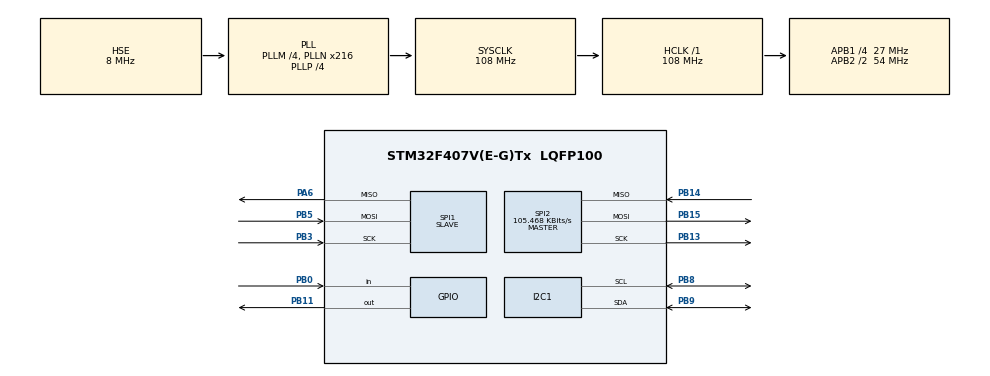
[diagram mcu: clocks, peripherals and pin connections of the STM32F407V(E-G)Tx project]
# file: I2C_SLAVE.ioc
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I2C1.GeneralCallMode=I2C_GENERALCALL_ENABLE
I2C1.OwnAddress=0x50
Mcu.Family=STM32F4
Mcu.Name=STM32F407V(E-G)Tx
Mcu.Package=LQFP100
NVIC.I2C1_ER_IRQn=true\:0\:0\:false\:false\:true\:true\:true
NVIC.I2C1_EV_IRQn=true\:0\:0\:false\:false\:true\:true\:true
NVIC.PriorityGroup=NVIC_PRIORITYGROUP_4
NVIC.SPI1_IRQn=true\:1\:0\:true\:false\:true\:true\:true
NVIC.SPI2_IRQn=true\:1\:0\:true\:false\:true\:true\:true
PA13.Mode=Serial_Wire
PA13.Signal=SYS_JTMS-SWDIO
PA14.Mode=Serial_Wire
PA14.Signal=SYS_JTCK-SWCLK
PA6.Mode=Full_Duplex_Slave
PA6.Signal=SPI1_MISO
PB0.Signal=GPIO_Input
PB11.GPIO_PuPd=GPIO_PULLUP
PB11.GPIO_Speed=GPIO_SPEED_FREQ_HIGH
PB11.PinState=GPIO_PIN_SET
PB11.Signal=GPIO_Output
PB13.Mode=Full_Duplex_Master
PB13.Signal=SPI2_SCK
PB14.Mode=Full_Duplex_Master
PB14.Signal=SPI2_MISO
PB15.Mode=Full_Duplex_Master
PB15.Signal=SPI2_MOSI
PB3.Mode=Full_Duplex_Slave
PB3.Signal=SPI1_SCK
PB5.Mode=Full_Duplex_Slave
PB5.Signal=SPI1_MOSI
PB8.Mode=I2C
PB8.Signal=I2C1_SCL
PB9.Mode=I2C
PB9.Signal=I2C1_SDA
PH0-OSC_IN.Mode=HSE-External-Oscillator
PH0-OSC_IN.Signal=RCC_OSC_IN
PH1-OSC_OUT.Mode=HSE-External-Oscillator
PH1-OSC_OUT.Signal=RCC_OSC_OUT
ProjectManager.HeapSize=0x200
ProjectManager.StackSize=0x400
ProjectManager.TargetToolchain=MDK-ARM V5.27
RCC.48MHZClocksFreq_Value=108000000
RCC.AHBFreq_Value=108000000
RCC.APB1CLKDivider=RCC_HCLK_DIV4
RCC.APB1Freq_Value=27000000
RCC.APB1TimFreq_Value=54000000
RCC.APB2CLKDivider=RCC_HCLK_DIV2
RCC.APB2Freq_Value=54000000
RCC.APB2TimFreq_Value=108000000
RCC.CortexFreq_Value=108000000
RCC.HCLKFreq_Value=108000000
RCC.HSE_VALUE=8000000
RCC.HSI_VALUE=16000000
RCC.LSE_VALUE=32768
RCC.PLLM=4
RCC.PLLN=216
RCC.PLLP=RCC_PLLP_DIV4
RCC.PLLSourceVirtual=RCC_PLLSOURCE_HSE
RCC.SYSCLKFreq_VALUE=108000000
RCC.SYSCLKSource=RCC_SYSCLKSOURCE_PLLCLK
RCC.VCOOutputFreq_Value=432000000
SPI1.Direction=SPI_DIRECTION_2LINES
SPI1.Mode=SPI_MODE_SLAVE
SPI1.VirtualType=VM_SLAVE
SPI2.BaudRatePrescaler=SPI_BAUDRATEPRESCALER_256
SPI2.CalculateBaudRate=105.468 KBits/s
SPI2.Direction=SPI_DIRECTION_2LINES
SPI2.Mode=SPI_MODE_MASTER
SPI2.VirtualType=VM_MASTER
board=custom

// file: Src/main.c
/* USER CODE BEGIN Header */
/**
  ******************************************************************************
  * @file           : main.c
  * @brief          : Main program body
  ******************************************************************************
  * @attention
  *
  * <h2><center>&copy; Copyright (c) 2020 STMicroelectronics.
  * All rights reserved.</center></h2>
  *
  * This software component is licensed by ST under BSD 3-Clause license,
  * the "License"; You may not use this file except in compliance with the
  * License. You may obtain a copy of the License at:
  *                        opensource.org/licenses/BSD-3-Clause
  *
  ******************************************************************************
  */
/* USER CODE END Header */

#include "main.h"
#include "i2c.h"
#include "spi.h"
#include "gpio.h"

/* USER CODE BEGIN Includes */
#include "string.h"
/* USER CODE END Includes */

/* USER CODE BEGIN PTD */
extern uint8_t slave_rec_buf[150];
extern uint8_t master_rec_buf[150];
/* USER CODE END PTD */

void SystemClock_Config(void);

int main(void)
{

  /* MCU Configuration--------------------------------------------------------*/

  /* Reset of all peripherals, Initializes the Flash interface and the Systick. */
  HAL_Init();

  /* Configure the system clock */
  SystemClock_Config();

  /* Initialize all configured peripherals */
  MX_GPIO_Init();
  MX_I2C1_Init();
  MX_SPI1_Init();
  MX_SPI2_Init();
  /* USER CODE BEGIN 2 */
//	slave_work();
		spi_slave_work();
  /* USER CODE END 2 */

  /* Infinite loop */
  /* USER CODE BEGIN WHILE */
  while (1)
  {
		spi_master_work();
    /* USER CODE END WHILE */

    /* USER CODE BEGIN 3 */
//		master_work();
//		memset(slave_rec_buf,0,150);
//		memset(master_rec_buf,0,150);
  }
  /* USER CODE END 3 */
}

void SystemClock_Config(void)
{
  RCC_OscInitTypeDef RCC_OscInitStruct = {0};
  RCC_ClkInitTypeDef RCC_ClkInitStruct = {0};

  /** Configure the main internal regulator output voltage
  */
  __HAL_RCC_PWR_CLK_ENABLE();
  __HAL_PWR_VOLTAGESCALING_CONFIG(PWR_REGULATOR_VOLTAGE_SCALE1);
  /** Initializes the CPU, AHB and APB busses clocks
  */
  RCC_OscInitStruct.OscillatorType = RCC_OSCILLATORTYPE_HSE;
  RCC_OscInitStruct.HSEState = RCC_HSE_ON;
  RCC_OscInitStruct.PLL.PLLState = RCC_PLL_ON;
  RCC_OscInitStruct.PLL.PLLSource = RCC_PLLSOURCE_HSE;
  RCC_OscInitStruct.PLL.PLLM = 4;
  RCC_OscInitStruct.PLL.PLLN = 216;
  RCC_OscInitStruct.PLL.PLLP = RCC_PLLP_DIV4;
  RCC_OscInitStruct.PLL.PLLQ = 4;
  if (HAL_RCC_OscConfig(&RCC_OscInitStruct) != HAL_OK)
  {
    Error_Handler();
  }
  /** Initializes the CPU, AHB and APB busses clocks
  */
  RCC_ClkInitStruct.ClockType = RCC_CLOCKTYPE_HCLK|RCC_CLOCKTYPE_SYSCLK
                              |RCC_CLOCKTYPE_PCLK1|RCC_CLOCKTYPE_PCLK2;
  RCC_ClkInitStruct.SYSCLKSource = RCC_SYSCLKSOURCE_PLLCLK;
  RCC_ClkInitStruct.AHBCLKDivider = RCC_SYSCLK_DIV1;
  RCC_ClkInitStruct.APB1CLKDivider = RCC_HCLK_DIV4;
  RCC_ClkInitStruct.APB2CLKDivider = RCC_HCLK_DIV2;

  if (HAL_RCC_ClockConfig(&RCC_ClkInitStruct, FLASH_LATENCY_3) != HAL_OK)
  {
    Error_Handler();
  }
}

void Error_Handler(void)
{
}

/************************ (C) COPYRIGHT STMicroelectronics *****END OF FILE****/
